# MU3E_ARB_HIT_TYPE0 register map
Vendor: Mu3e; Series: MU3E_FPGA_IP; File version: 26.6.5.0518
CMSIS-SVD description of one arb_hit_type0 lane's CSR aperture. The supercore instantiates 8 lanes; each lane's CSR is a 32-word (128 B) window decoded from offsets 0x00..0x74 per the RTL csr_read_data case in rtl/arb_hit_type0_csr.sv.
Registers are 32-bit, read-only, reset 0x0 unless marked. A register's access mark holds for its fields unless they carry their own. Offsets are from the block's base; lines under a group give offsets from that group; [hi:lo] are bit positions; {n}, {i} and the like mark numbered series; 'fields as' and 'values as' point back to an identical list; <NAME> marks a mode.

## Memory map
0x00000000 ARB_HIT_TYPE0_CSR size 0x80 — Per-lane arbiter CSR. UID at offset 0x00, META mux at 0x04, runtime mode + status, watchdog + idle counters, protocol/drop-mid-packet error counters with syndromes, and live + latched-snapshot counters for ingress/drop/egress on real and emu paths plus frame counters.

## ARB_HIT_TYPE0_CSR — Per-lane arbiter CSR. UID at offset 0x00, META mux at 0x04, runtime mode + status, watchdog + idle counters, protocol/drop-mid-packet error counters with syndromes, and live + latched-snapshot counters for ingress/drop/egress on real and emu paths plus frame counters.
Base 0x00000000
0x00 UID reset 0x41485430 — Software-visible IP identifier. Default ASCII "AHT0" (0x41485430).
  [31:0] value
0x04 META rw — Read-multiplexed metadata word. Write page selector (0=VERSION, 1=DATE, 2=GIT, 3=INSTANCE_ID) then read META.
  [1:0] page_sel
0x08 MODE_PENDING — Pending mode-change request bit. Reads as 1 while a mode swap is queued.
  [1:0] mode_pending
0x0C STATUS — Live arbiter status flags: ingress/egress FIFO states, watchdog timeout, current mode (REAL / EMU / MIX_RR).
  [31:0] value
0x10 WATCHDOG_CYCLES rw — Watchdog timer reload value in cycles for mid-packet-drop detection.
  [15:0] value
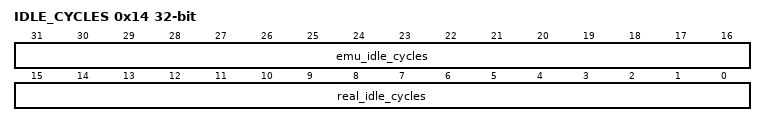
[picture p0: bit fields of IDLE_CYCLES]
0x14 IDLE_CYCLES — Packed idle-cycle counters: real_idle_cycles[15:0], emu_idle_cycles[31:16]. Counts cycles the real / emu ingress lane was idle.
  [31:16] emu_idle_cycles, [15:0] real_idle_cycles
0x18 ERROR_COUNT_PROTOCOL — Sticky count of arbiter protocol errors (handshake/STARTOFPACKET/EOP).
  [31:0] value
0x1C ERROR_COUNT_DROP_MID_PACKET — Count of drops that occurred mid-packet (watchdog-triggered or downstream backpressure).
  [31:0] value
0x20 SYNDROME_PROTOCOL — Last-event syndrome word for protocol errors. Encodes the source/state at the moment the error was registered.
  [31:0] value
0x24 SYNDROME_DROP_MID_PACKET — Last-event syndrome word for the mid-packet drop counter.
  [31:0] value
0x28 INGRESS_REAL_HITS — Live ingress-hit count from the real (MuTRiG) source, low 32 bits.
  [31:0] value
0x2C INGRESS_REAL_HITS_H_SNAP — Frozen snapshot of INGRESS_REAL_HITS for atomic high/low read pairing.
  [31:0] value
0x30 INGRESS_EMU_HITS — Live ingress-hit count from the emulator source, low 32 bits.
  [31:0] value
0x34 INGRESS_EMU_HITS_H_SNAP — Frozen snapshot of INGRESS_EMU_HITS.
  [31:0] value
0x38 DROPS_REAL — Live drop count for the real source, low 32 bits.
  [31:0] value
0x3C DROPS_REAL_H_SNAP — Frozen snapshot of DROPS_REAL.
  [31:0] value
0x40 DROPS_EMU — Live drop count for the emu source, low 32 bits.
  [31:0] value
0x44 DROPS_EMU_H_SNAP — Frozen snapshot of DROPS_EMU.
  [31:0] value
0x48 EGRESS_REAL_HITS — Live egress-hit count (arbiter accepted, downstream consumed) for the real source.
  [31:0] value
0x4C EGRESS_REAL_HITS_H_SNAP — Frozen snapshot of EGRESS_REAL_HITS.
  [31:0] value
0x50 EGRESS_EMU_HITS — Live egress-hit count for the emu source.
  [31:0] value
0x54 EGRESS_EMU_HITS_H_SNAP — Frozen snapshot of EGRESS_EMU_HITS.
  [31:0] value
0x58 INGRESS_REAL_FRAMES — Live ingress-frame count for the real source.
  [31:0] value
0x5C INGRESS_REAL_FRAMES_H_SNAP — Frozen snapshot of INGRESS_REAL_FRAMES.
  [31:0] value
0x60 INGRESS_EMU_FRAMES — Live ingress-frame count for the emu source.
  [31:0] value
0x64 INGRESS_EMU_FRAMES_H_SNAP — Frozen snapshot of INGRESS_EMU_FRAMES.
  [31:0] value
0x68 EGRESS_REAL_FRAMES — Live egress-frame count for the real source.
  [31:0] value
0x6C EGRESS_REAL_FRAMES_H_SNAP — Frozen snapshot of EGRESS_REAL_FRAMES.
  [31:0] value
0x70 EGRESS_EMU_FRAMES — Live egress-frame count for the emu source.
  [31:0] value
0x74 EGRESS_EMU_FRAMES_H_SNAP — Frozen snapshot of EGRESS_EMU_FRAMES.
  [31:0] value
